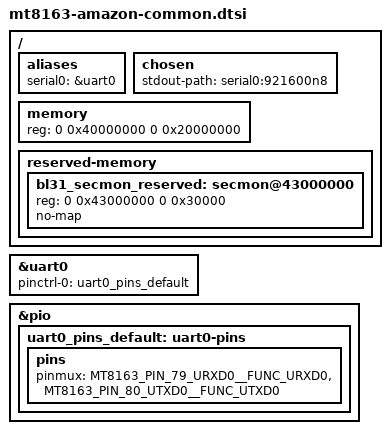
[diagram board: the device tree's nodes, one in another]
// SPDX-License-Identifier: GPL-2.0-only OR MIT
/*
 * Copyright (c) 2025-2026 Ben Grisdale <bengris32@protonmail.ch>
 */

#include "mt8163.dtsi"

/ {
	aliases {
		serial0 = &uart0;
	};

	chosen {
		stdout-path = "serial0:921600n8";
	};

	memory {
		device_type = "memory";
		reg = <0 0x40000000 0 0x20000000>;
	};

	reserved-memory {
		#address-cells = <2>;
		#size-cells = <2>;
		ranges;

		/* 128 KiB reserved for ARM Trusted Firmware (BL31) */
		bl31_secmon_reserved: secmon@43000000 {
			reg = <0 0x43000000 0 0x30000>;
			no-map;
		};
	};
};

&uart0 {
	pinctrl-names = "default";
	pinctrl-0 = <&uart0_pins_default>;
	status = "okay";
};

&pio {
	uart0_pins_default: uart0-pins {
		pins {
			pinmux = <MT8163_PIN_79_URXD0__FUNC_URXD0>,
				 <MT8163_PIN_80_UTXD0__FUNC_UTXD0>;
		};
	};
};
